# cslr_psc register map
Vendor: Texas Instruments
Peripheral module from a debugger description file (folder tci6486).
Registers are 32-bit, access not given, reset 0x0 unless marked. A register's access mark holds for its fields unless they carry their own. Offsets are as the file gives them; lines under a group give offsets from that group; [hi:lo] are bit positions; {n}, {i} and the like mark numbered series; 'fields as' and 'values as' point back to an identical list; <NAME> marks a mode.

## PSC — Power and Sleep Controller
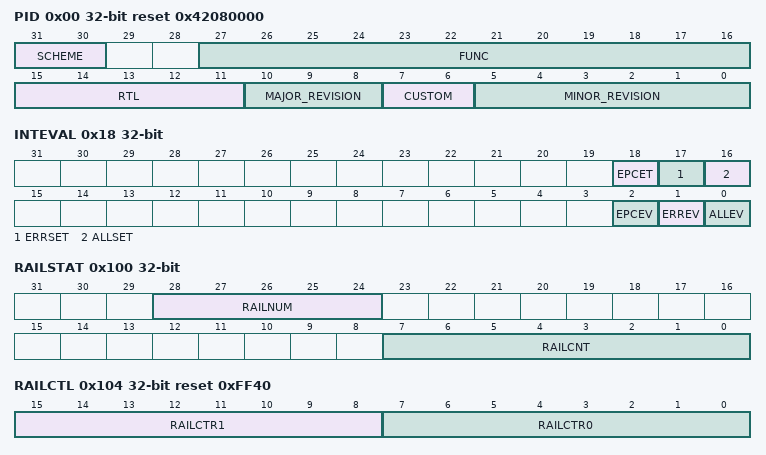
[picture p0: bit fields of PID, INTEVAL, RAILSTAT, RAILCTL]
0x00 PID reset 0x42080000 — Peripheral ID Register
  [31:30] SCHEME ro — Used to distinguish between old scheme and current
  [27:16] FUNC ro — Indicating a software compatible module family
    1=PSC2.0 (Start with 1 for PSC 2.0)
  [15:11] RTL ro — RTL Version
    0=PSC1.0 (Start with 0 for PSC 1.0)
  [10:8] MAJOR_REVISION ro
  [7:6] CUSTOM ro — Indicating a Special Version for a particular device
  [5:0] MINOR_REVISION ro
0x10 GBLCTL — Global Control Register
  [0] FORCE rw — Force Bit
0x18 INTEVAL — Interrupt Evaluation Register
  [18] EPCET wo — External Power Control Interrupt Set
    0=Noeffect (Write of 0 has No effect); 1=causesthePSC_EPCINTtobepulsed (Write of 1 causes the PSC_EPCINT to be pulsed)
  [17] ERRSET wo — Error Interrupt Set
    0=Noeffect (Write of 0 has No effect); 1=causesthePSC_ERRINTtobepulsed (Write of 1 causes the PSC_ERRINT to be pulsed)
  [16] ALLSET wo — Combined Interrupt Set
    0=Noeffect (Write of 0 has No effect); 1=causesthePSC_ALLINTtobepulsed (Write of 1 causes the PSC_ALLINT to be pulsed)
  [2] EPCEV wo — External Power Control Interrupt
    0=Noeffect (Write of 0 has No effect); 1=Re-evaluateexternalpowercontrolinterruptPSC_EPCINT (Write of 1 re-evaluate external power control interrupt PSC_EPCINT)
  [1] ERREV wo — Re-Evaluate Error Interrupt
    0=NoEffect (Write of 0 has no effect); 1=Re-evaluateerrorinterruptPSC_ERRINT (Write of 1 Re-evaluate error interrupt PSC_ERRINT)
  [0] ALLEV wo — Re-Evaluate Combined PSC Interrupt
    0=Noeffect (Write of 0 has No effect); 1=Re-evaluatethecombinedPSCinterruptPSC_ALLINT (Write of 1 re-evaluate the Combined PSC interrupt PSC_ALLINT)
0x40 MERRPR0 ro — Module Error Pending Register
  [31:0] MEPR — Module n Error Condition
    0=Noerror (Write of 0 ;Module n has No error condition); 1=Error (Write of 1;Module n has error condition)
0x50 MERRCR0 ro — Module Error Clear Register
  [31:0] MECR — Module n Error Condition
    0=Noerror (Write of 0 has No effect); 1=causestheMERRPRbitntobecleared (Write of 1 to bit n causes the MERRPR bit n to be cleared)
0x60 PERRPR ro — Power Error Pending Register
  [31:0] PEPR — Power Domain m Error Condition
    0=Noerror (Power Domain m does not Error Condition); 1=Error (Power Domain m has Error Condition)
0x68 MERRCR wo — Power Error Clear Register
  [31:0] PECR — Power Domain m Clear Condition
    0=Noerror (Write of 0 has No effect); 1=causesthePERRPRbitntobecleared (Write of 1 to bit n causes the PERRPR bit n to be cleared)
0x70 EPCPR ro — External Power Control Pending Register
  [31:0] EPCPR — External Power Control Intervention Request for Power Domain n
    0=NoNeedExternalPower (No need for external power control to turn on/off power for power domain n); 1=ExternalPowerNeeded (External power control should turn on/off power for power domain n)
0x78 EPCCR wo — External Power Control Clear Register
  [31:0] EPCCR
    0=Noeffect (Write of 0 has No effect); 1=causesEPCPRbitntobecleared (Write of 1 to bit n causes the EPCPR bit n to be cleared)
0x100 RAILSTAT — Power Rail Status Register
  [28:24] RAILNUM ro — Indicates the current rail Requestor begin processed by GPSC
    0=AlwaysON (Defaults to 0 indicating Always ON domain that has no rail request/grant associated with it)
  [7:0] RAILCNT ro — Indicates the current rail counter value
0x104 RAILCTL reset 0xFF40 — Power Rail Counter Control Register
  [15:8] RAILCTR1 rw — Rail Counter Value 1
  [7:0] RAILCTR0 rw — Rail Counter Value 0
0x108 RAILSEL reset 0x3FF — Power Rail Counter Select
  [9:0] P rw — Rail Counter Select for Power Domain n
    0=UseRAILCTL.RailCtr0countvalueforpowerdomainn (0:Use RAILCTL.RailCtr0 count value for power domain n)
0x120 PTCMD wo — Power Transtion Command Register
  [31:0] G0 — Power Domain n GO Transition
    0=Noeffect (Writes of 0 have no effect); 1=SetscorrespondingPTSTAT.GOSTATfiled (Writes of 1 sets corresponding PTSTAT.GOSTAT filed, which causes PSC hardware to evaluate PDCTL.NEXT and MDCTL.NEXT)
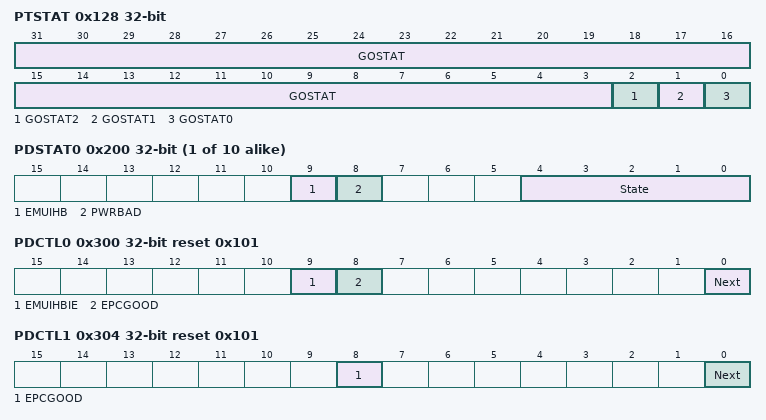
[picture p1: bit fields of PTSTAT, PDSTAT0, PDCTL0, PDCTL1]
0x128 PTSTAT ro — Power Domain Transition Status
  [31:3] GOSTAT — Power Domain n Transition Command Status
    0=Notransitionsinprogressinpowerdomainn (0:No transitions in progress in power domain n); 1=PowerDomainntransisitoninprogress (1:Power Domainn n transisiton in progress)
  [2] GOSTAT2 — Power Domain 1 Transition Command Status
    0=Notransitionsinprogressinpowerdomain2 (0:No transitions in progress in power domain 2); 1=PowerDomain2transisitoninprogress (1:Power Domain n transisiton in progress)
  [1] GOSTAT1 — Power Domain 1 Transition Command Status
    0=Notransitionsinprogressinpowerdomain1 (0:No transitions in progress in power domain 1); 1=PowerDomain1transisitoninprogress (1:Power Domain 1 transisiton in progress)
  [0] GOSTAT0 — Power Domain 0 Transition command status
    0=Notransitionsinprogressinpowerdomain0 (0:No transitions in progress in power domain 0); 1=PowerDomain0transisitoninprogress (1:Power Domain 0 transisiton in progress)
{0x200+4i} PDSTAT{i} (i=0..9) — Power Domain Status Register
  [9] EMUIHB ro — Emulation Alters Domain State
    0=Noemulationalteringuserdesiredpoerdomainstate; 1=Emulationaltersuser-desiredpowerstate
  [8] PWRBAD ro — Power Bad Error
    0=NoError; 1=ErrorDetected
  [4:0] State ro — Current Power Domain State
0x300 PDCTL0 reset 0x101 — Power Domain Control Register
  [9] EMUIHBIE rw — Emulation Alters Domain State
    0=notenabled; 1=interruptenabled
  [8] EPCGOOD rw — External Power Control Power Good Indication
    0=ExternalPowerControlhasturnedoffpowertothisdomain; 1=ExternalPowerControlhasturnedonpowertothisdomain
  [0] Next rw — User-Desired Next Power Domain State
    0=Off; 1=On
0x304 PDCTL1 reset 0x101 — Power Domain Control Register
  [8] EPCGOOD rw — External Power Control Power Good Indication
    0=ExternalPowerControlhasturnedoffpowertothisdomain; 1=ExternalPowerControlhasturnedonpowertothisdomain; 0=notenabled; 1=interruptenabled
  [0] Next rw — User-Desired Next Power Domain State
    0=Off; 1=On
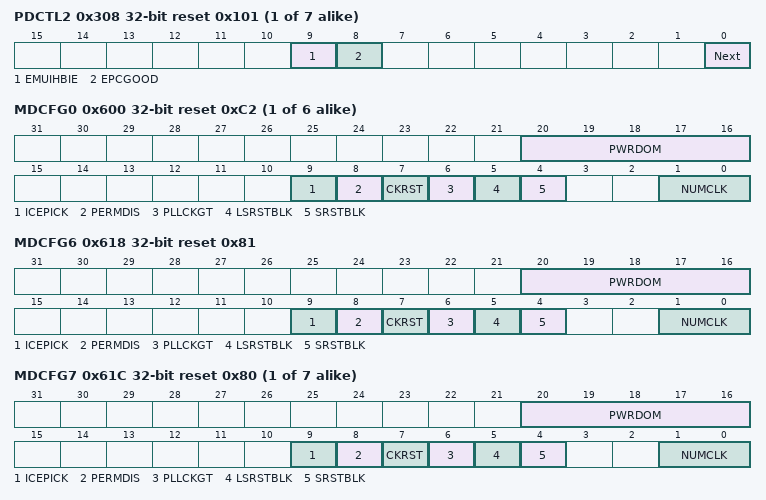
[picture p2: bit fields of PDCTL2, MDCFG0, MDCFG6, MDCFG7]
{0x300+4i} PDCTL{i} reset 0x101 (i=2..8) — Power Domain Control Register
  fields as PDCTL0
{0x600+4i} MDCFG{i} reset 0xC2 (i=0..5) — Module Configuration Register
  [20:16] PWRDOM ro — Power Domain
  [9] ICEPICK — IcePick support
    0=noicepicksuuport; 1=supportsicepick
  [8] PERMDIS ro — Permanently Disable
    0=Notpermanentlydisablemodule; 1=Permanentlydisablemodule
  [7] CKRST ro — Modclk during MSM reset source assert
    0=LPSCdoesnotgivemodclkwhenitsMSMresetsourceisasserted; 1=LPSCgivesmodclkevenwhentheMSMresetsourceisasserted
  [6] PLLCKGT ro — PLL Clock Gate
    0=LPSCgatesmodclkdirectly; 1=LPSCdoesnotgatemodclkdirectly
  [5] LSRSTBLK ro — LRST Soft Reset Block
  [4] SRSTBLK ro — Soft Reset Block
    0=Softresetsarenotblocked; 1=Softresetsareblocked
  [1:0] NUMCLK ro — Number of modclks supported on LPSC
    0=1modclk; 1=2modclks; 2=3modclks; 3=4modclks
0x618 MDCFG6 reset 0x81 — Module Configuration Register
  fields as MDCFG0
{0x600+4i} MDCFG{i} reset 0x80 (i=7..13) — Module Configuration Register
  fields as MDCFG0
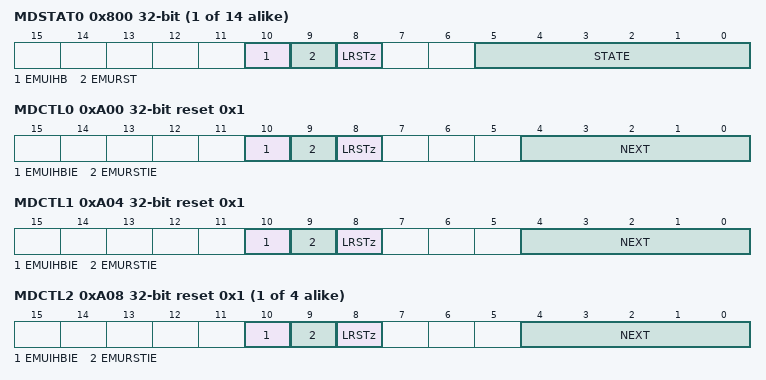
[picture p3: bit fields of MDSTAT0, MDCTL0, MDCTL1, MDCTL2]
{0x800+4i} MDSTAT{i} (i=0..13) — Module Status Register
  [10] EMUIHB ro — Emulation Alters Module State
    0=Noemulation; 1=Emulationaltersuser-desiredmodulestate
  [9] EMURST ro — Emulation Alters Reset to Module
    0=Noemulation; 1=Emulationhasalteredmodulereset
  [8] LRSTz ro — Module Local Reset Actual Status
    0=LocalResetAsserted; 1=LocalResetDe-asserted
  [5:0] STATE ro — These bits indicate the current module state
0xA00 MDCTL0 reset 0x1 — Module Control Register
  [10] EMUIHBIE rw — Emulation Alters Module State
    0=notenable; 1=interruptenabled
  [9] EMURSTIE rw — Emulation Alter Reset Interrupt Enable
    0=notenabled; 1=interruptenable
  [8] LRSTz rw — Module local reset control
    0=assertlocalreset; 1=de-assertlocalreset
  [4:0] NEXT rw — Module Next State
    0=SwRstDisable; 1=SyncRst; 16=Disable; 17=Enable
0xA04 MDCTL1 reset 0x1 — Module Control Register
  [10] EMUIHBIE rw — Emulation Alters Module State
    0=notenable
  [9] EMURSTIE rw — Emulation Alter Reset Interrupt Enable
    0=notenabled; 1=interruptenable
  [8] LRSTz rw — Module local reset control
    0=assertlocalreset; 1=de-assertlocalreset
  [4:0] NEXT rw — Module Next State
    0=SwRstDisable; 1=SyncRst; 16=Disable; 17=Enable
{0xA00+4i} MDCTL{i} reset 0x1 (i=2..5) — Module Control Register
  fields as MDCTL0
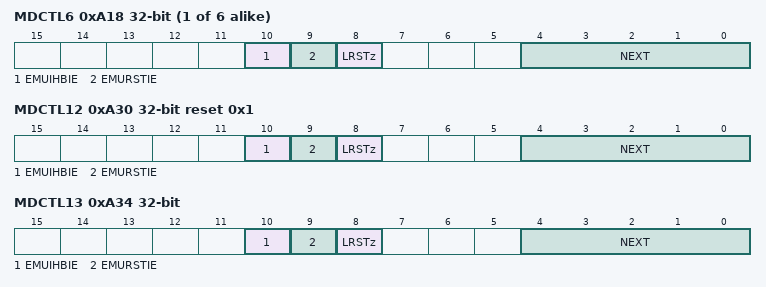
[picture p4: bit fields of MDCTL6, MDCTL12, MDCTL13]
{0xA00+4i} MDCTL{i} (i=6..11) — Module Control Register
  fields as MDCTL0
0xA30 MDCTL12 reset 0x1 — Module Control Register
  fields as MDCTL0
0xA34 MDCTL13 — Module Control Register
  fields as MDCTL0
